# COMPUTE_CLUSTER0_CTL_CFG_PI register map
Vendor: Texas Instruments
Registers are 32-bit, read-write, reset 0x0 unless marked. A register's access mark holds for its fields unless they carry their own. Offsets are as the file gives them; [hi:lo] are bit positions; {n}, {i} and the like mark numbered series.

## COMPUTE_CLUSTER0_CTL_CFG_PI (part 2 of 2)
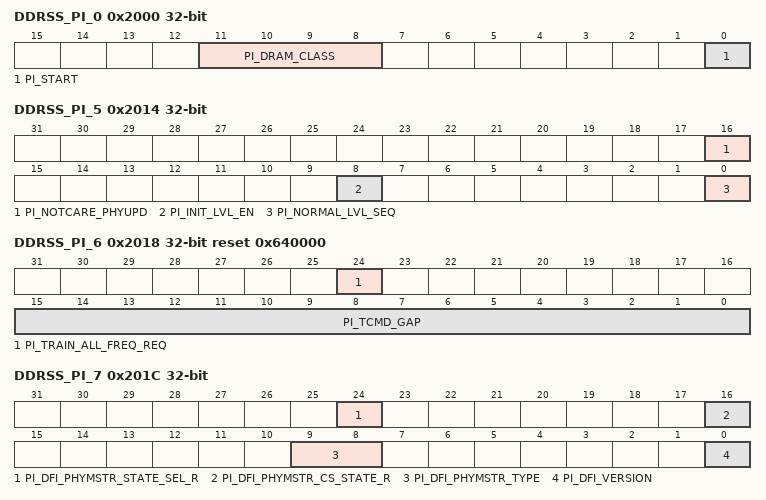
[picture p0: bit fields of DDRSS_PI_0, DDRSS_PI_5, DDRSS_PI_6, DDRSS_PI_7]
0x2000 DDRSS_PI_0
  [11:8] PI_DRAM_CLASS — Defines the memory class for the PI.Bh - LPDDR4All other values reserved
  [0] PI_START — Initiate command processing in the PI.
0x2004 DDRSS_PI_1 ro reset 0xCB1E3F21
  [31:0] PI_VERSION_0 — Holds the PI version number.
0x2008 DDRSS_PI_2 ro reset 0x78D9209
  [31:0] PI_VERSION_1 — Holds the PI version number.
0x200C DDRSS_PI_3 ro reset 0x1387
  [15:0] PI_ID — Holds the PI ID number.
0x2010 DDRSS_PI_4 ro
  [31:0] PI_UNUSED_REG_0 — Unused register
0x2014 DDRSS_PI_5
  [16] PI_NOTCARE_PHYUPD — Allow the PI to issue a master request to the controller if a phyupd_req from the PHY has been detected.
  [8] PI_INIT_LVL_EN — Enables the initial leveling sequence after PI initialization procedure.
  [0] PI_NORMAL_LVL_SEQ — Enable the PI to finish all the pending leveling before releasing the DFI bus.
0x2018 DDRSS_PI_6 access per field reset 0x640000
  [24] PI_TRAIN_ALL_FREQ_REQ wo — Triggers training for all supported frequencies in PI_FREQ_MAP.
  [15:0] PI_TCMD_GAP rw — Specifies the minimum gap in DFI clocks between two commands.
0x201C DDRSS_PI_7
  [24] PI_DFI_PHYMSTR_STATE_SEL_R — DFI PHY Master State Select: Indication from the PHY to the MC whether the requested memory state is IDLE or Self refresh.
  [16] PI_DFI_PHYMSTR_CS_STATE_R — This signal indicates the state of the DRAM when the PHY becomes the master.
  [9:8] PI_DFI_PHYMSTR_TYPE — DFI Master Request Type used for dfi 4.1 verision: This signal indicates the required state of DRAM when PHY becomes the master.
  [0] PI_DFI_VERSION — Define the DFI master version, set 1 for DFI4.1, set 0 for DFI4.0
0x2020 DDRSS_PI_8 ro
  [31:0] PI_TDFI_PHYMSTR_MAX — Indicates the maximum number of DFI clock cycles registered while the dfi_phymstr_req signal is asserted and the dfi_phymstr_ack signal is asserted.
0x2024 DDRSS_PI_9 ro
  [19:0] PI_TDFI_PHYMSTR_RESP — Indicates the maximum number of DFI clock cycles registered between a dfi_phymstr_req signal assertion and a dfi_phymstr_ack signal assertion.
0x2028 DDRSS_PI_10 ro
  [19:0] PI_TDFI_PHYUPD_RESP — Indicates the maximum number of DFI clock cycles registered between a dfi_phyupd_req signal assertion and a dfi_phyupd_ack signal assertion.
0x202C DDRSS_PI_11 ro
  [31:0] PI_TDFI_PHYUPD_MAX — Indicates the maximum number of DFI clock cycles registered while the dfi_phyupd_req signal is asserted and the dfi_phy_ack signal is asserted.
0x2030 DDRSS_PI_12
  [31:0] PI_FREQ_MAP — Frequency map for supported working frequencies.
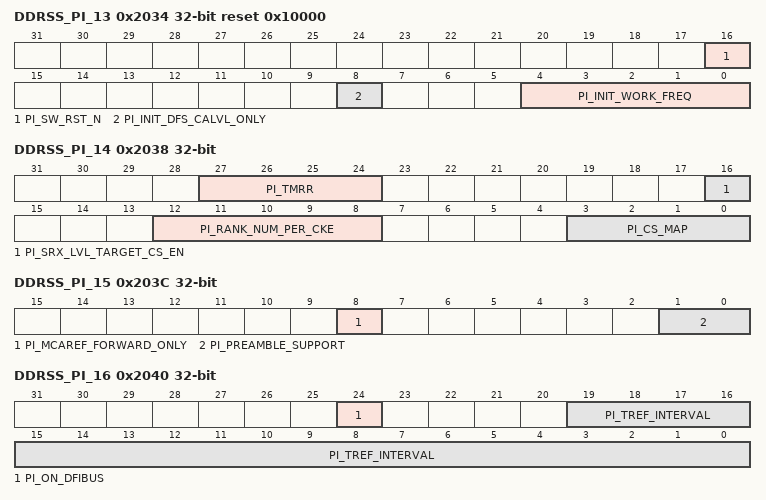
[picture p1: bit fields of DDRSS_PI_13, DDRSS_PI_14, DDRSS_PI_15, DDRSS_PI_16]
0x2034 DDRSS_PI_13 reset 0x10000
  [16] PI_SW_RST_N — User request to reset the whole PI except the parameter modules.
  [8] PI_INIT_DFS_CALVL_ONLY — Enables frequency training for CA leveling only.
  [4:0] PI_INIT_WORK_FREQ — Indicates the initial work frequency after initialization and initial leveling sequence.
0x2038 DDRSS_PI_14
  [27:24] PI_TMRR — DRAM tMRR value in memory clock cycles.
  [16] PI_SRX_LVL_TARGET_CS_EN — Defines self refresh exit trigger target rank/ranks training or all ranks training.
  [12:8] PI_RANK_NUM_PER_CKE — Defines the number of chip selects share one cke
  [3:0] PI_CS_MAP — Defines which chip selects are active.
0x203C DDRSS_PI_15
  [8] PI_MCAREF_FORWARD_ONLY — Controls the generation of AREF from the PI module or forward the MC received value.
  [1:0] PI_PREAMBLE_SUPPORT — Defines the read and write preamble length.
0x2040 DDRSS_PI_16 access per field
  [24] PI_ON_DFIBUS ro — Monitors the state of the PI controlling the DFI bus.
  [19:0] PI_TREF_INTERVAL rw — Defines the cycles between refreshes to different chip selects.
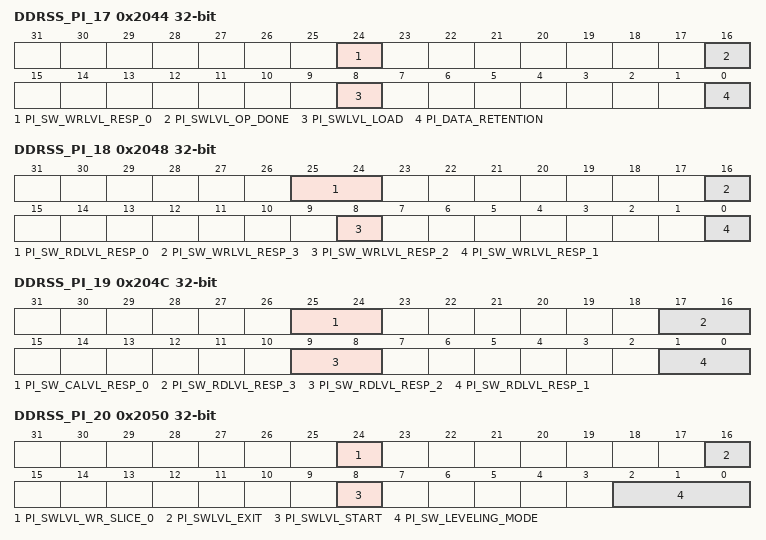
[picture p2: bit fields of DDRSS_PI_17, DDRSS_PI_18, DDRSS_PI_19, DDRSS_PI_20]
0x2044 DDRSS_PI_17 access per field
  [24] PI_SW_WRLVL_RESP_0 ro — Write leveling response for data slice 0.
  [16] PI_SWLVL_OP_DONE ro — Reports the status of the software leveling operation.
  [8] PI_SWLVL_LOAD wo — User request to load delays and execute software leveling.
  [0] PI_DATA_RETENTION ro — Monitors the readiness for the PHY to be put into data retention mode after pi_sref_entry req parameter has been written.
0x2048 DDRSS_PI_18 ro
  [25:24] PI_SW_RDLVL_RESP_0 — Read leveling response for data slice 0.
  [16] PI_SW_WRLVL_RESP_3 — Write leveling response for data slice 3.
  [8] PI_SW_WRLVL_RESP_2 — Write leveling response for data slice 2.
  [0] PI_SW_WRLVL_RESP_1 — Write leveling response for data slice 1.
0x204C DDRSS_PI_19 ro
  [25:24] PI_SW_CALVL_RESP_0 — CA leveling response for address slice 0.
  [17:16] PI_SW_RDLVL_RESP_3 — Read leveling response for data slice 3.
  [9:8] PI_SW_RDLVL_RESP_2 — Read leveling response for data slice 2.
  [1:0] PI_SW_RDLVL_RESP_1 — Read leveling response for data slice 1.
0x2050 DDRSS_PI_20 access per field
  [24] PI_SWLVL_WR_SLICE_0 wo — SW leveling write command in WDQ training.
  [16] PI_SWLVL_EXIT wo — User request to exit software leveling.
  [8] PI_SWLVL_START wo — User request to initiate software leveling of type in the SW_LEVELING_MODE parameter.
  [2:0] PI_SW_LEVELING_MODE rw — Defines the leveling operation for software leveling.
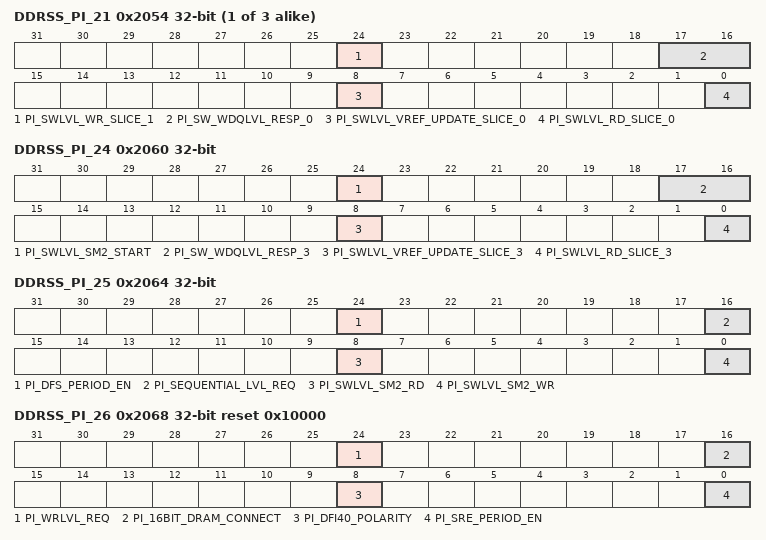
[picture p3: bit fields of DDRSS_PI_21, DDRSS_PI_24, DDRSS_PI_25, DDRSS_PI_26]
{0x2000+4i} DDRSS_PI_{i} access per field (i=21..23)
  [24] PI_SWLVL_WR_SLICE_{i-20} wo — SW leveling write command in WDQ training.
  [17:16] PI_SW_WDQLVL_RESP_{i-21} ro — Leveling response for data slice {i-21}.
  [8] PI_SWLVL_VREF_UPDATE_SLICE_{i-21} wo — SW leveling vref update command in WDQ training.
  [0] PI_SWLVL_RD_SLICE_{i-21} wo — SW leveling read command in WDQ training.
0x2060 DDRSS_PI_24 access per field
  [24] PI_SWLVL_SM2_START wo — SW leveling start command for stage 2.
  [17:16] PI_SW_WDQLVL_RESP_3 ro — Leveling response for data slice 3.
  [8] PI_SWLVL_VREF_UPDATE_SLICE_3 wo — SW leveling vref update command in WDQ training.
  [0] PI_SWLVL_RD_SLICE_3 wo — SW leveling read command in WDQ training.
0x2064 DDRSS_PI_25 access per field
  [24] PI_DFS_PERIOD_EN rw — Enable the DFS triggered periodic leveling.
  [16] PI_SEQUENTIAL_LVL_REQ wo — User request to initiate all possible leveling sequences.
  [8] PI_SWLVL_SM2_RD wo — SW leveling read command for stage 2.
  [0] PI_SWLVL_SM2_WR wo — SW leveling write command for stage 2.
0x2068 DDRSS_PI_26 access per field reset 0x10000
  [24] PI_WRLVL_REQ wo — User request to initiate write leveling.
  [16] PI_16BIT_DRAM_CONNECT rw — Enable 16/32 bit DRAM configuration.
  [8] PI_DFI40_POLARITY rw — Defines the polarity of the dfi_wrdata_cs_n/dfi_rddata_cs_n signals.
  [0] PI_SRE_PERIOD_EN rw — Enable the self refresh exit triggered periodic leveling.
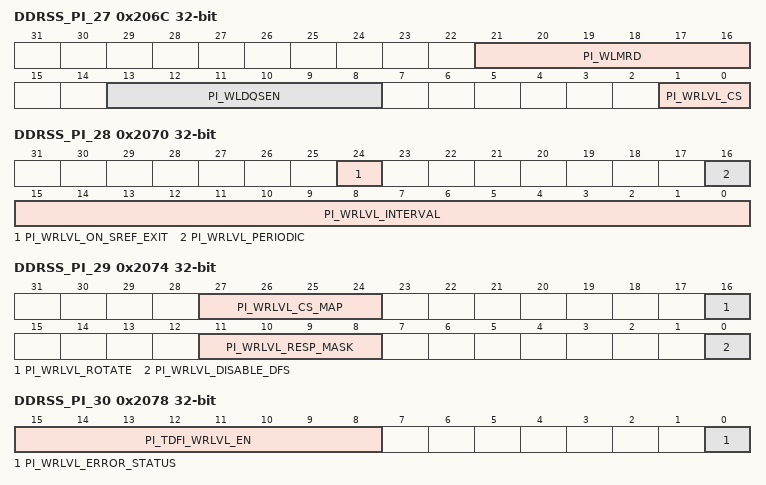
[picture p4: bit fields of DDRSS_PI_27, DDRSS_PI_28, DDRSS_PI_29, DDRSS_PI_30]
0x206C DDRSS_PI_27
  [21:16] PI_WLMRD — Delay from issuing MRS to first write leveling strobe.
  [13:8] PI_WLDQSEN — Delay from issuing MRS to first DQS strobe for write leveling.
  [1:0] PI_WRLVL_CS — Specifies the target chip select for the write leveling operation initiated through the WRLVL_REQ parameter.
0x2070 DDRSS_PI_28
  [24] PI_WRLVL_ON_SREF_EXIT — Enables automatic write leveling on a self-refresh exit.
  [16] PI_WRLVL_PERIODIC — Enables the use of the dfi_lvl_periodic signal during write leveling.
  [15:0] PI_WRLVL_INTERVAL — Number of long count sequences counted between automatic write leveling commands.
0x2074 DDRSS_PI_29
  [27:24] PI_WRLVL_CS_MAP — Defines the chip select map for write leveling operations.
  [16] PI_WRLVL_ROTATE — Enables rotational CS for counter triggered automatic write leveling.
  [11:8] PI_WRLVL_RESP_MASK — Mask for the dfi_wrlvl_resp signal during write leveling.
  [0] PI_WRLVL_DISABLE_DFS — Disable automatic write leveling on freq change.
0x2078 DDRSS_PI_30 access per field
  [15:8] PI_TDFI_WRLVL_EN rw — Defines the DFI tWRLVL_EN timing parameter (in DFI clocks), the minimum cycles from a dfi_wrlvl_en assertion to the first dfi_wrlvl_strobe assertion.
  [0] PI_WRLVL_ERROR_STATUS ro — Holds the error associated with the write level error interrupt.
0x207C DDRSS_PI_31
  [31:0] PI_TDFI_WRLVL_RESP — Defines the DFI tWRLVL_RESP timing parameter (in DFI clocks), the maximum cycles between a dfi_wrlvl_req assertion and a dfi_wrlvl_en assertion.
0x2080 DDRSS_PI_32
  [31:0] PI_TDFI_WRLVL_MAX — Defines the DFI tWRLVL_MAX timing parameter (in DFI clocks), the maximum cycles between a dfi_wrlvl_en assertion and a valid dfi_wrlvl_resp.
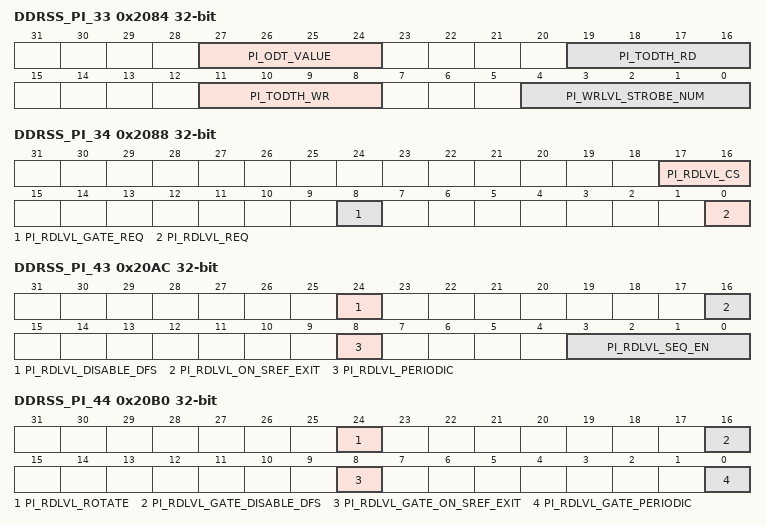
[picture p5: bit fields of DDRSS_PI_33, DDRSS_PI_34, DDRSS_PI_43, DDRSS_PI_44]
0x2084 DDRSS_PI_33
  [27:24] PI_ODT_VALUE — When using LPDDR4, this value will be driven out on the dfi_odt signal.
  [19:16] PI_TODTH_RD — Defines the minimum DRAM cycles of ODT high time for a read command, in memory clocks.
  [11:8] PI_TODTH_WR — Defines the minimum DRAM cycles of ODT high time for a write command, in memory clocks.
  [4:0] PI_WRLVL_STROBE_NUM — Defines the number of write leveling strobes generated.
0x2088 DDRSS_PI_34 access per field
  [17:16] PI_RDLVL_CS rw — Specifies the target chip select for the data eye training operation initiated through the RDLVL_REQ parameter or the gate training operation initiated through the RDLVL_GATE_REQ parameter.
  [8] PI_RDLVL_GATE_REQ wo — User request to initiate gate training.
  [0] PI_RDLVL_REQ wo — User request to initiate data eye training.
{0x2000+4i} DDRSS_PI_{i} (i=35..42)
  [31:0] PI_RDLVL_PAT_{i-35} — Non-default pattern {i-35} used for read data eye training of DDR4 or LPDDR4, and read dbi training of DDR4.
0x20AC DDRSS_PI_43
  [24] PI_RDLVL_DISABLE_DFS — Disables automatic data eye training on freq change.
  [16] PI_RDLVL_ON_SREF_EXIT — Enables automatic data eye training on a self-refresh exit.
  [8] PI_RDLVL_PERIODIC — Enables the use of the dfi_lvl_periodic signal during data eye training.
  [3:0] PI_RDLVL_SEQ_EN — Specifies the pattern, format and MPR for data eye training.
0x20B0 DDRSS_PI_44
  [24] PI_RDLVL_ROTATE — Enables rotational CS for interval data eye training.
  [16] PI_RDLVL_GATE_DISABLE_DFS — Disables automatic gate training on freq change.
  [8] PI_RDLVL_GATE_ON_SREF_EXIT — Enables automatic gate training on a self-refresh exit.
  [0] PI_RDLVL_GATE_PERIODIC — Enables the use of the dfi_lvl_periodic signal during gate training.
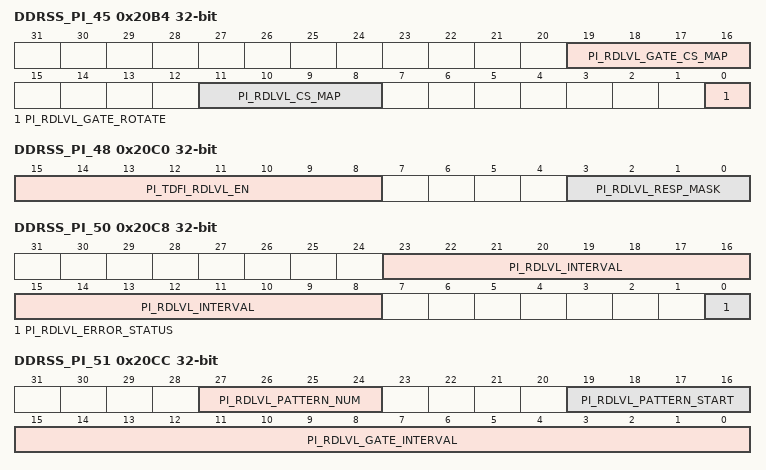
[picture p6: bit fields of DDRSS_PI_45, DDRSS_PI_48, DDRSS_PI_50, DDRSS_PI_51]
0x20B4 DDRSS_PI_45
  [19:16] PI_RDLVL_GATE_CS_MAP — Defines the chip select map for gate training operations.
  [11:8] PI_RDLVL_CS_MAP — Defines the chip select map for data eye training operations.
  [0] PI_RDLVL_GATE_ROTATE — Enables rotational CS for interval gate training.
0x20B8 DDRSS_PI_46
  [9:0] PI_TDFI_RDLVL_RR — Defines the DFI tRDLVL_RR timing parameter (in DFI clocks), the minimum cycles between read commands.
0x20BC DDRSS_PI_47
  [31:0] PI_TDFI_RDLVL_RESP — Defines the DFI tRDLVL_RESP timing parameter (in DFI clocks), the maximum cycles between a dfi_rdlvl_req or dfi_rdlvl_gate_req assertion and a dfi_rdlvl_en or dfi_rdlvl_gate_en assertion.
0x20C0 DDRSS_PI_48
  [15:8] PI_TDFI_RDLVL_EN — Defines the DFI tRDLVL_EN timing parameter (in DFI clocks), the minimum cycles from a dfi_rdlvl_en or dfi_rdlvl_gate_en assertion to the first read or MRR.
  [3:0] PI_RDLVL_RESP_MASK — Mask for the dfi_rdlvl_resp signal during data eye training.
0x20C4 DDRSS_PI_49
  [31:0] PI_TDFI_RDLVL_MAX — Defines the DFI tRDLVL_MAX timing parameter (in DFI clocks), the maximum cycles between a dfi_rdlvl_en or dfi_rdlvl_gate_en assertion and a valid dfi_rdlvl_resp.
0x20C8 DDRSS_PI_50 access per field
  [23:8] PI_RDLVL_INTERVAL rw — Number of long count sequences counted between automatic data eye training commands.
  [0] PI_RDLVL_ERROR_STATUS ro — Holds the error associated with the data eye training error or gate training error interrupt.
0x20CC DDRSS_PI_51
  [27:24] PI_RDLVL_PATTERN_NUM — Defines the number of pattern supported in read leveling.
  [19:16] PI_RDLVL_PATTERN_START — Defines the start pattern in read leveling.
  [15:0] PI_RDLVL_GATE_INTERVAL — Number of long count sequences counted between automatic gate training commands.
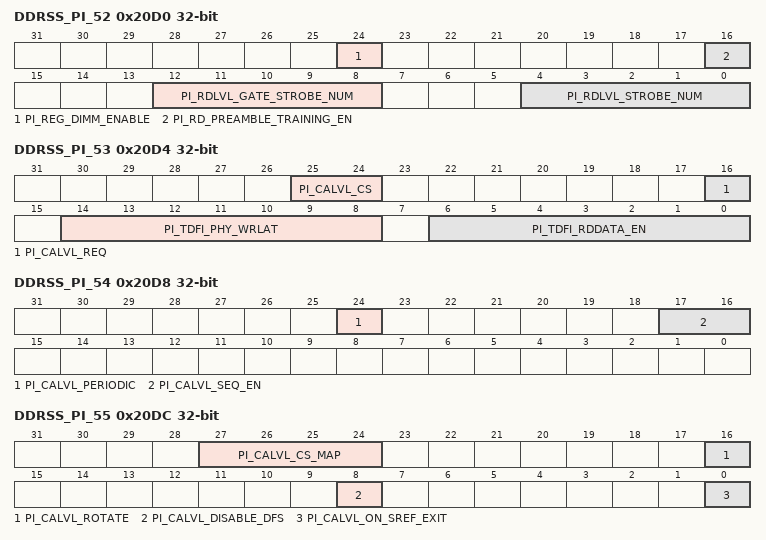
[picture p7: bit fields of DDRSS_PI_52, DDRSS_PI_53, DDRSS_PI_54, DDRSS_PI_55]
0x20D0 DDRSS_PI_52
  [24] PI_REG_DIMM_ENABLE — Enable registered DIMM operation.
  [16] PI_RD_PREAMBLE_TRAINING_EN — Enable read preamble training during gate training.
  [12:8] PI_RDLVL_GATE_STROBE_NUM — Defines the number of back to back MPC command in one read process in read gate training.
  [4:0] PI_RDLVL_STROBE_NUM — Defines the number of back to back MPC command in one read process in read eye training.
0x20D4 DDRSS_PI_53 access per field
  [25:24] PI_CALVL_CS rw — Specifies the target chip select for the CA training operation initiated through the CALVL_REQ parameter.
  [16] PI_CALVL_REQ wo — User request to initiate CA training.
  [14:8] PI_TDFI_PHY_WRLAT ro — Holds the calculated DFI tPHY_WRLAT timing parameter (in DFI PHY clocks), the maximum cycles between a write command and a dfi_wrdata_en assertion.
  [6:0] PI_TDFI_RDDATA_EN ro — Holds the calculated DFI tRDDATA_EN timing parameter (in DFI PHY clocks), the maximum cycles between a read command and a dfi_rddata_en assertion.
0x20D8 DDRSS_PI_54
  [24] PI_CALVL_PERIODIC — Enables the use of the dfi_lvl_periodic signal during CA training.
  [17:16] PI_CALVL_SEQ_EN — Specifies which CA training patterns will be used.
0x20DC DDRSS_PI_55
  [27:24] PI_CALVL_CS_MAP — Defines the chip select map for CA training operations.
  [16] PI_CALVL_ROTATE — Enables rotational CS for interval CA training.
  [8] PI_CALVL_DISABLE_DFS — Disables automatic CA training on freq change.
  [0] PI_CALVL_ON_SREF_EXIT — Enables automatic CA training on a self-refresh exit.
0x20E0 DDRSS_PI_56
  [7:0] PI_TDFI_CALVL_EN — Defines the DFI tCALVL_EN timing parameter (in DFI clocks), the minimum cycles between a dfi_calvl_en assertion and a dfi_cke de-assertion.
0x20E4 DDRSS_PI_57
  [31:0] PI_TDFI_CALVL_RESP — Defines the DFI tCALVL_RESP timing parameter (in DFI clocks), the maximum cycles between a dfi_calvl_req assertion and a dfi_calvl_en assertion.
0x20E8 DDRSS_PI_58
  [31:0] PI_TDFI_CALVL_MAX — Defines the DFI tCALVL_MAX timing parameter (in DFI clocks), the maximum cycles between a dfi_calvl_en assertion and a valid dfi_calvl_resp.
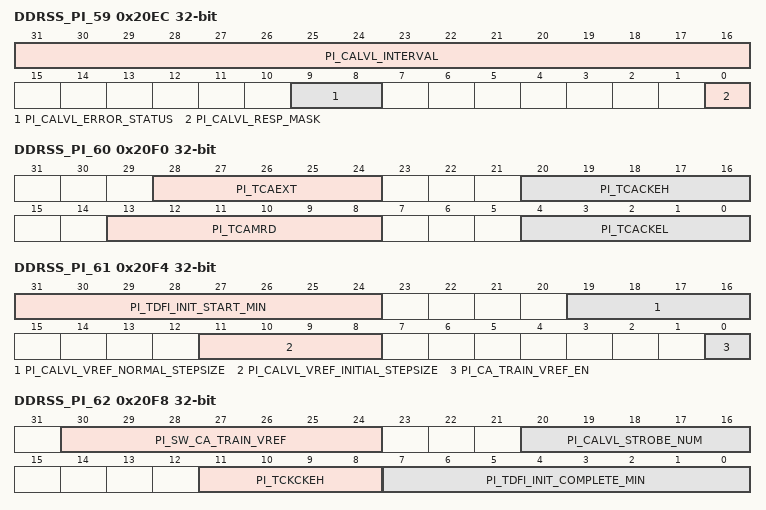
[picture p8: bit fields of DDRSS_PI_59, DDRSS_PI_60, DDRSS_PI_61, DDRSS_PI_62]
0x20EC DDRSS_PI_59 access per field
  [31:16] PI_CALVL_INTERVAL rw — Number of long count sequences counted between automatic CA training commands.
  [9:8] PI_CALVL_ERROR_STATUS ro — Holds the error associated with the CA training error interrupt.
  [0] PI_CALVL_RESP_MASK rw — Mask for the dfi_calvl_resp signal during CA training.
0x20F0 DDRSS_PI_60
  [28:24] PI_TCAEXT — DRAM tCAEXT value in memory cycles.
  [20:16] PI_TCACKEH — DRAM tCACKEH value in memory cycles.
  [13:8] PI_TCAMRD — DRAM tCAMRD value in memory cycles.
  [4:0] PI_TCACKEL — DRAM tCACKEL value in memory cycles.
0x20F4 DDRSS_PI_61
  [31:24] PI_TDFI_INIT_START_MIN — Minimum number of DFI clocks before dfi_init_start can be driven after a previous command/training event.
  [19:16] PI_CALVL_VREF_NORMAL_STEPSIZE — The adjust step for the post-initial Vref(ca) training.
  [11:8] PI_CALVL_VREF_INITIAL_STEPSIZE — The adjust step for the initial Vref(ca) training.
  [0] PI_CA_TRAIN_VREF_EN — Control for VREF training during CA training post power-on initialization.
0x20F8 DDRSS_PI_62
  [30:24] PI_SW_CA_TRAIN_VREF — The Vref value which is set for SW step by step CA training.
  [20:16] PI_CALVL_STROBE_NUM — The consecutive dfi_calvl_strobe number when updating the CA vref data.
  [11:8] PI_TCKCKEH — DRAM tCKELCK Clock and command valid before CKE HIGH.
  [7:0] PI_TDFI_INIT_COMPLETE_MIN — Minimum number of DFI clocks from dfi_init_complete to a command/training event.
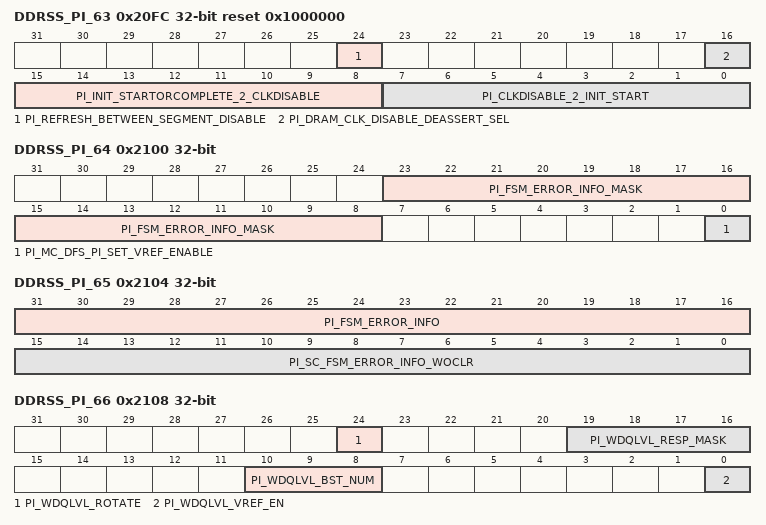
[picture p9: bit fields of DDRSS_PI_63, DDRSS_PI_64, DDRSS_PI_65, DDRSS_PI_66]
0x20FC DDRSS_PI_63 reset 0x1000000
  [24] PI_REFRESH_BETWEEN_SEGMENT_DISABLE — Disable the refresh between CA first and second segment training.
  [16] PI_DRAM_CLK_DISABLE_DEASSERT_SEL — Indicate dfi_dram_clk_disable deassert following dfi_init_start deassert or dfi_init_complete assert.
  [15:8] PI_INIT_STARTORCOMPLETE_2_CLKDISABLE — Defines the delay from deasserting of dfi_init_start or asserting of dfi_init_complete to deasserting of dfi_dram_clk_disable in DFI clock.
  [7:0] PI_CLKDISABLE_2_INIT_START — Defines the delay from the asserting of dfi_dram_clk_disable to the asserting of dfi_init_start in DFI clock.
0x2100 DDRSS_PI_64
  [23:8] PI_FSM_ERROR_INFO_MASK
  [0] PI_MC_DFS_PI_SET_VREF_ENABLE — Enable the PI to set VREF value after DFS issued by MC.
0x2104 DDRSS_PI_65 access per field
  [31:16] PI_FSM_ERROR_INFO ro — Gather each fsm error bit.
  [15:0] PI_SC_FSM_ERROR_INFO_WOCLR wo — PI FSM Error Info.
0x2108 DDRSS_PI_66
  [24] PI_WDQLVL_ROTATE — Enables write DQ training rotate for interval training.
  [19:16] PI_WDQLVL_RESP_MASK — Write DQ training response mask.
  [10:8] PI_WDQLVL_BST_NUM — Defines the number of write/read bursts issued at each step in write DQ training.
  [0] PI_WDQLVL_VREF_EN — Control for VREF training as part of non-initialization write DQ training.
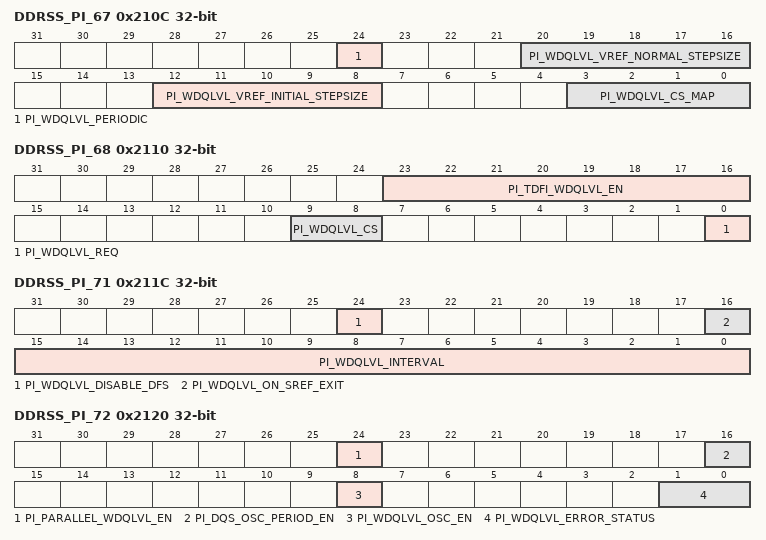
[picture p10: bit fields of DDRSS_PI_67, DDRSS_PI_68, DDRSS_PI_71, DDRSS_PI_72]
0x210C DDRSS_PI_67
  [24] PI_WDQLVL_PERIODIC — Enables periodic write DQ training.
  [20:16] PI_WDQLVL_VREF_NORMAL_STEPSIZE — Write DQ training vref step size for post_initial training.
  [12:8] PI_WDQLVL_VREF_INITIAL_STEPSIZE — Write DQ training vref step size for initial training.
  [3:0] PI_WDQLVL_CS_MAP — Map of CS's included in write DQ training sequence.
0x2110 DDRSS_PI_68 access per field
  [23:16] PI_TDFI_WDQLVL_EN rw — DFI timing param tWDQLVL_EN.
  [9:8] PI_WDQLVL_CS rw — Write DQ training target chip select.
  [0] PI_WDQLVL_REQ wo — SW write to initiate Write DQ training request.
0x2114 DDRSS_PI_69
  [31:0] PI_TDFI_WDQLVL_RESP — DFI timing param tWDQLVL_RESP.
0x2118 DDRSS_PI_70
  [31:0] PI_TDFI_WDQLVL_MAX — DFI timing param tWDQLVL_MAX.
0x211C DDRSS_PI_71
  [24] PI_WDQLVL_DISABLE_DFS — Disable automatic write DQ training on freq change.
  [16] PI_WDQLVL_ON_SREF_EXIT — Issue a write DQ training command on self-refresh exit.
  [15:0] PI_WDQLVL_INTERVAL — Sets the maximum number of long count sequences allowed between automatic write DQ training operations.
0x2120 DDRSS_PI_72 access per field
  [24] PI_PARALLEL_WDQLVL_EN rw — Enable per rank parallel Write DQ training for LPDDR4,
  [16] PI_DQS_OSC_PERIOD_EN rw — Enable for DQS oscillator triggered periodic write DQ training,
  [8] PI_WDQLVL_OSC_EN rw — Enable for DQS oscillator triggered write DQ training,
  [1:0] PI_WDQLVL_ERROR_STATUS ro — Holds the error associated with the write dq level error interrupt.
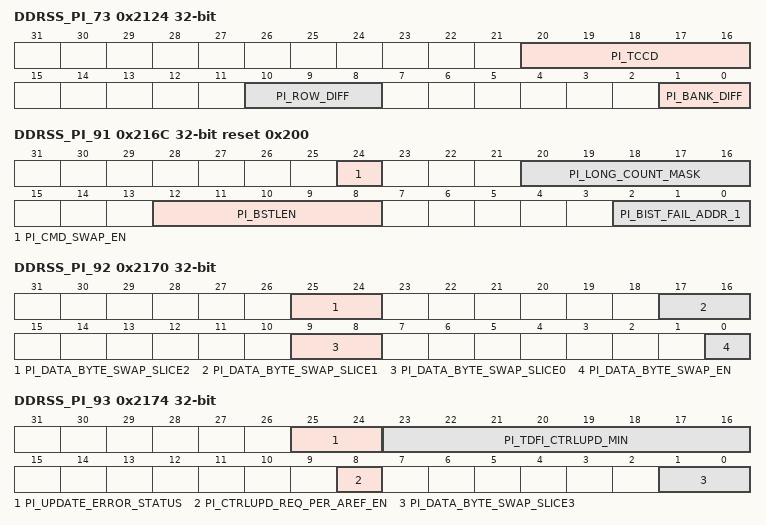
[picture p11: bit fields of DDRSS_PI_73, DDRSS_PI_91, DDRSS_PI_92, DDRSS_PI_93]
0x2124 DDRSS_PI_73
  [20:16] PI_TCCD — DRAM CAS-to-CAS value in cycles.
  [10:8] PI_ROW_DIFF — Difference between number of address pins available and number being used.
  [1:0] PI_BANK_DIFF — Difference between number of bank pins available and number being used.
0x2128 DDRSS_PI_74 reset 0x2000200 (reset mask 0xF0F0F0F)
0x212C DDRSS_PI_75 reset 0x1000100 (reset mask 0xF0F0F0F)
0x2130 DDRSS_PI_76 reset 0x1000000 (reset mask 0xF0F0F0F)
0x2134 DDRSS_PI_77 reset 0x2000200 (reset mask 0xF0F0F0F)
0x2138 DDRSS_PI_78 reset 0x200 (reset mask 0xF0F0F)
0x213C DDRSS_PI_79 ro
  [27:0] PI_INT_STATUS — Status of interrupt features in the PI.
0x2140 DDRSS_PI_80 wo
  [26:0] PI_INT_ACK — Clear the corresponding interrupt bit of the PI_INT_STATUS parameter.
0x2144 DDRSS_PI_81
  [27:0] PI_INT_MASK — Mask for PI_int signals from the PI_INT_STATUS parameter.
{0x2000+4i} DDRSS_PI_{i} ro (i=82..85)
  [31:0] PI_BIST_EXP_DATA_{i-82} — Expected data on BIST error.
{0x2000+4i} DDRSS_PI_{i} ro (i=86..89)
  [31:0] PI_BIST_FAIL_DATA_{i-86} — Actual data on BIST error.
0x2168 DDRSS_PI_90 ro
  [31:0] PI_BIST_FAIL_ADDR_0 — The burst aligned address of BIST error.
0x216C DDRSS_PI_91 access per field reset 0x200
  [24] PI_CMD_SWAP_EN rw — Command pin swap function enable
  [20:16] PI_LONG_COUNT_MASK rw — Reduces the length of the long counter from 1024 cycles.
  [12:8] PI_BSTLEN rw — Encoded burst length sent to DRAMs during initialization.
  [2:0] PI_BIST_FAIL_ADDR_1 ro — The burst aligned address of BIST error.
0x2170 DDRSS_PI_92
  [25:24] PI_DATA_BYTE_SWAP_SLICE2 — DATA pin 2 mux selector
  [17:16] PI_DATA_BYTE_SWAP_SLICE1 — DATA pin 1 mux selector
  [9:8] PI_DATA_BYTE_SWAP_SLICE0 — DATA pin 0 mux selector
  [0] PI_DATA_BYTE_SWAP_EN — DATA pin swap function enable
0x2174 DDRSS_PI_93 access per field
  [25:24] PI_UPDATE_ERROR_STATUS ro — Identifies the source of any DFI PI-initiated update errors.
  [23:16] PI_TDFI_CTRLUPD_MIN rw — Reports the DFI tCTRLUPD_MIN timing parameter (in DFI clocks), the minimum cycles that dfi_ctrlupd_req must be asserted.
  [8] PI_CTRLUPD_REQ_PER_AREF_EN rw — Enable an automatic PI initiated update (dfi_ctrlupd_req) after every refresh.
  [1:0] PI_DATA_BYTE_SWAP_SLICE3 rw — DATA pin 3 mux selector
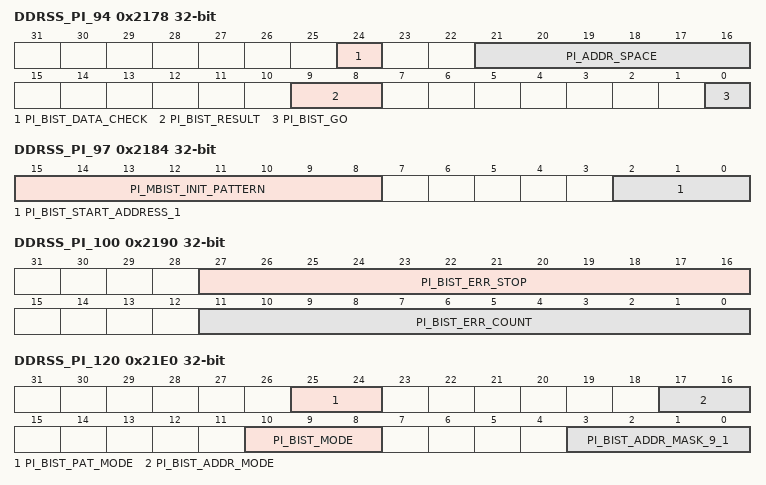
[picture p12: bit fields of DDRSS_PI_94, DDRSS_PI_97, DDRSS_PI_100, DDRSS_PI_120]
0x2178 DDRSS_PI_94 access per field
  [24] PI_BIST_DATA_CHECK rw — Enable data checking with BIST operation.
  [21:16] PI_ADDR_SPACE rw — Sets the number of address bits to check during BIST operation.
  [9:8] PI_BIST_RESULT ro — BIST operation status (pass/fail).
  [0] PI_BIST_GO rw — Initiate a BIST operation.
0x217C DDRSS_PI_95
  [0] PI_BIST_ADDR_CHECK — Enable address checking with BIST operation.
0x2180 DDRSS_PI_96
  [31:0] PI_BIST_START_ADDRESS_0 — Start BIST checking at this address.
0x2184 DDRSS_PI_97
  [15:8] PI_MBIST_INIT_PATTERN — PI mbist data check, random lfsr pattern mode init pattern seed.
  [2:0] PI_BIST_START_ADDRESS_1 — Start BIST checking at this address.
0x2188 DDRSS_PI_98
  [31:0] PI_BIST_DATA_MASK_0 — Mask applied to data for BIST error checking.
0x218C DDRSS_PI_99
  [31:0] PI_BIST_DATA_MASK_1 — Mask applied to data for BIST error checking.
0x2190 DDRSS_PI_100 access per field
  [27:16] PI_BIST_ERR_STOP rw — Defines the maximum number of error occurrences allowed prior to quitting when the BIST_TEST_MODE parameter is set to 1, 2 or 3.
  [11:0] PI_BIST_ERR_COUNT ro — Indicates the number of BIST errors found when the BIST_TEST_MODE parameter is set to 1, 2 or 3.
0x2194 DDRSS_PI_101
  [31:0] PI_BIST_ADDR_MASK_0_0 — Defines an address to be masked during the BIST operation..
0x2198 DDRSS_PI_102
  [3:0] PI_BIST_ADDR_MASK_0_1 — Defines an address to be masked during the BIST operation..
0x219C DDRSS_PI_103
  [31:0] PI_BIST_ADDR_MASK_1_0 — Defines an address to be masked during the BIST operation..
0x21A0 DDRSS_PI_104
  [3:0] PI_BIST_ADDR_MASK_1_1 — Defines an address to be masked during the BIST operation..
0x21A4 DDRSS_PI_105
  [31:0] PI_BIST_ADDR_MASK_2_0 — Defines an address to be masked during the BIST operation..
0x21A8 DDRSS_PI_106
  [3:0] PI_BIST_ADDR_MASK_2_1 — Defines an address to be masked during the BIST operation..
0x21AC DDRSS_PI_107
  [31:0] PI_BIST_ADDR_MASK_3_0 — Defines an address to be masked during the BIST operation..
0x21B0 DDRSS_PI_108
  [3:0] PI_BIST_ADDR_MASK_3_1 — Defines an address to be masked during the BIST operation..
0x21B4 DDRSS_PI_109
  [31:0] PI_BIST_ADDR_MASK_4_0 — Defines an address to be masked during the BIST operation..
0x21B8 DDRSS_PI_110
  [3:0] PI_BIST_ADDR_MASK_4_1 — Defines an address to be masked during the BIST operation..
0x21BC DDRSS_PI_111
  [31:0] PI_BIST_ADDR_MASK_5_0 — Defines an address to be masked during the BIST operation..
0x21C0 DDRSS_PI_112
  [3:0] PI_BIST_ADDR_MASK_5_1 — Defines an address to be masked during the BIST operation..
0x21C4 DDRSS_PI_113
  [31:0] PI_BIST_ADDR_MASK_6_0 — Defines an address to be masked during the BIST operation..
0x21C8 DDRSS_PI_114
  [3:0] PI_BIST_ADDR_MASK_6_1 — Defines an address to be masked during the BIST operation..
0x21CC DDRSS_PI_115
  [31:0] PI_BIST_ADDR_MASK_7_0 — Defines an address to be masked during the BIST operation..
0x21D0 DDRSS_PI_116
  [3:0] PI_BIST_ADDR_MASK_7_1 — Defines an address to be masked during the BIST operation..
0x21D4 DDRSS_PI_117
  [31:0] PI_BIST_ADDR_MASK_8_0 — Defines an address to be masked during the BIST operation..
0x21D8 DDRSS_PI_118
  [3:0] PI_BIST_ADDR_MASK_8_1 — Defines an address to be masked during the BIST operation..
0x21DC DDRSS_PI_119
  [31:0] PI_BIST_ADDR_MASK_9_0 — Defines an address to be masked during the BIST operation..
0x21E0 DDRSS_PI_120
  [25:24] PI_BIST_PAT_MODE — Sets the pattern mode of BIST.
  [17:16] PI_BIST_ADDR_MODE — Sets the address traversing order of BIST.
  [10:8] PI_BIST_MODE — Sets the BIST data checking mode.
  [3:0] PI_BIST_ADDR_MASK_9_1 — Defines an address to be masked during the BIST operation..
{0x2000+4i} DDRSS_PI_{i} (i=121..124)
  [31:0] PI_BIST_USER_PAT_{i-121} — Sets the user-specified pattern of BIST.
0x21F4 DDRSS_PI_125
  [3:0] PI_BIST_PAT_NUM — Sets the max used pattern number of BIST from a total of 8 built-in patterns.
{0x2000+4i} DDRSS_PI_{i} (i=126..133)
  [29:0] PI_BIST_STAGE_{i-126} — Sets the programmable algorithm of each stage X when pi_bist_mmode = 'h4.
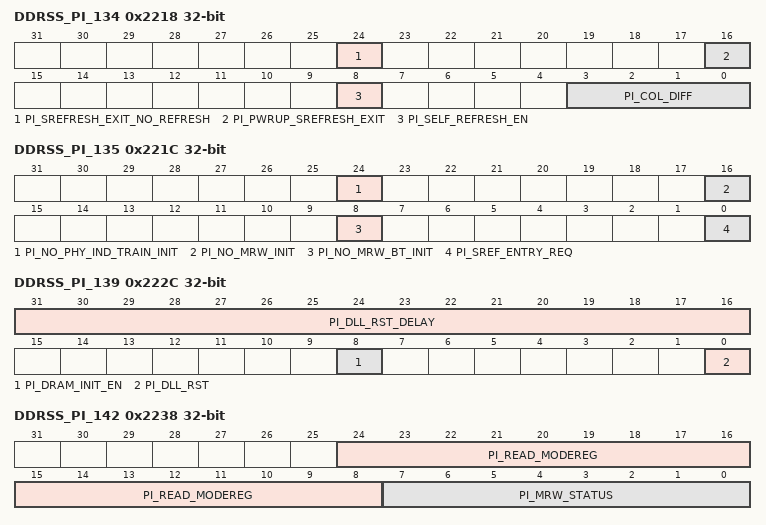
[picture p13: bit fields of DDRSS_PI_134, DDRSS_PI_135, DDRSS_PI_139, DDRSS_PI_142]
0x2218 DDRSS_PI_134
  [24] PI_SREFRESH_EXIT_NO_REFRESH — Disables the automatic refresh request associated with self-refresh exit.
  [16] PI_PWRUP_SREFRESH_EXIT — Allow powerup via self-refresh instead of full memory initialization.
  [8] PI_SELF_REFRESH_EN — Control for PI to enable self refresh mode.
  [3:0] PI_COL_DIFF — Difference between number of column pins available and number being used.
0x221C DDRSS_PI_135 access per field
  [24] PI_NO_PHY_IND_TRAIN_INIT rw — Disable PHY Independent Training during initialization.
  [16] PI_NO_MRW_INIT rw — Disable MRW commands after training during initialization.
  [8] PI_NO_MRW_BT_INIT rw — Disable MRW commands before training during initialization.
  [0] PI_SREF_ENTRY_REQ wo — In PI power up data retention, PI can issued sref entry command.
0x2220 DDRSS_PI_136
  [0] PI_NO_AUTO_MRR_INIT — Disable MRR commands during initialization.
0x2224 DDRSS_PI_137
  [31:0] PI_TRST_PWRON — Duration of memory reset during power-on initialization.
0x2228 DDRSS_PI_138
  [31:0] PI_CKE_INACTIVE — Number of cycles after reset before CKE will be active.
0x222C DDRSS_PI_139
  [31:16] PI_DLL_RST_DELAY — Minimum cycles required for DLL reset signal dll_rst_n to be held.
  [8] PI_DRAM_INIT_EN — Control for the initialization of DRAM by the PI.
  [0] PI_DLL_RST — Enables use of the DLL reset (dll_rst_n).
0x2230 DDRSS_PI_140
  [7:0] PI_DLL_RST_ADJ_DLY — Minimum cycles after setting master delay in DLL until the DLL reset signal dll_rst_n may be asserted.
0x2234 DDRSS_PI_141
  [25:0] PI_WRITE_MODEREG — Write memory mode register data to the DRAMs.
0x2238 DDRSS_PI_142 access per field
  [24:8] PI_READ_MODEREG rw — Read the specified memory mode register from specified chip when start bit set.
  [7:0] PI_MRW_STATUS ro — Write memory mode register status.
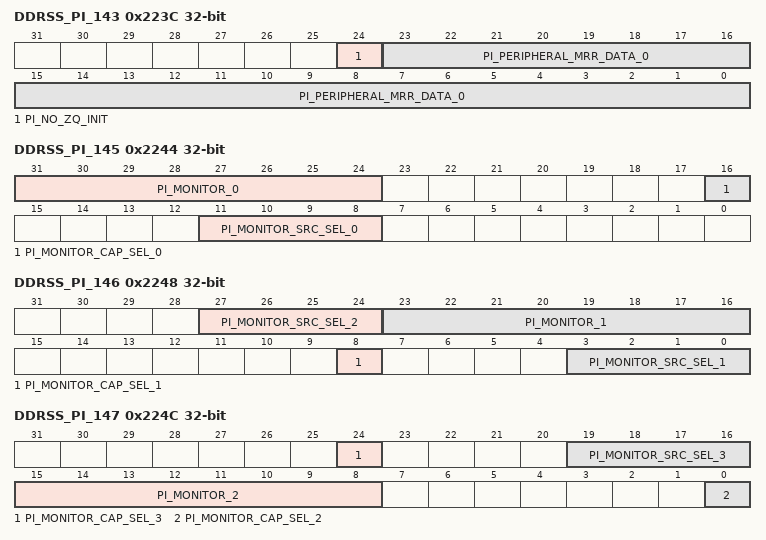
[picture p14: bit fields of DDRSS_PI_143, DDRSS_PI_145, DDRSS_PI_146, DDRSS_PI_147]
0x223C DDRSS_PI_143 access per field
  [24] PI_NO_ZQ_INIT rw — Disable ZQ operations during initialization.
  [23:0] PI_PERIPHERAL_MRR_DATA_0 ro — Data and chip returned from memory mode register read requested by the READ_MODEREG parameter, Bits (
0x2240 DDRSS_PI_144 access per field
  [16] PI_ZQ_REQ_PENDING ro — Indicates that a ZQ command is currently in progress or waiting to run.
0x2244 DDRSS_PI_145 access per field
  [31:24] PI_MONITOR_0 ro — Monitor register 0.
  [16] PI_MONITOR_CAP_SEL_0 rw — Selection of captures for pi_monitor_0.
  [11:8] PI_MONITOR_SRC_SEL_0 rw — Selection of sources for pi_monitor_0.
0x2248 DDRSS_PI_146 access per field
  [27:24] PI_MONITOR_SRC_SEL_2 rw — Selection of sources for pi_monitor_2.
  [23:16] PI_MONITOR_1 ro — Monitor register 1.
  [8] PI_MONITOR_CAP_SEL_1 rw — Selection of captures for pi_monitor_1.
  [3:0] PI_MONITOR_SRC_SEL_1 rw — Selection of sources for pi_monitor_1.
0x224C DDRSS_PI_147 access per field
  [24] PI_MONITOR_CAP_SEL_3 rw — Selection of captures for pi_monitor_3.
  [19:16] PI_MONITOR_SRC_SEL_3 rw — Selection of sources for pi_monitor_3.
  [15:8] PI_MONITOR_2 ro — Monitor register 2.
  [0] PI_MONITOR_CAP_SEL_2 rw — Selection of captures for pi_monitor_2.
0x2250 DDRSS_PI_148 access per field
  [31:24] PI_MONITOR_4 ro — Monitor register 4.
  [16] PI_MONITOR_CAP_SEL_4 rw — Selection of captures for pi_monitor_4.
  [11:8] PI_MONITOR_SRC_SEL_4 rw — Selection of sources for pi_monitor_4.
  [7:0] PI_MONITOR_3 ro — Monitor register 3.
0x2254 DDRSS_PI_149 access per field
  [27:24] PI_MONITOR_SRC_SEL_6 rw — Selection of sources for pi_monitor_6.
  [23:16] PI_MONITOR_5 ro — Monitor register 5.
  [8] PI_MONITOR_CAP_SEL_5 rw — Selection of captures for pi_monitor_5.
  [3:0] PI_MONITOR_SRC_SEL_5 rw — Selection of sources for pi_monitor_5.
0x2258 DDRSS_PI_150 access per field
  [24] PI_MONITOR_CAP_SEL_7 rw — Selection of captures for pi_monitor_7.
  [19:16] PI_MONITOR_SRC_SEL_7 rw — Selection of sources for pi_monitor_7.
  [15:8] PI_MONITOR_6 ro — Monitor register 6.
  [0] PI_MONITOR_CAP_SEL_6 rw — Selection of captures for pi_monitor_6.
0x225C DDRSS_PI_151 ro
  [7:0] PI_MONITOR_7 — Monitor register 7.
0x2260 DDRSS_PI_152 wo
  [7:0] PI_MONITOR_STROBE — Strobe the pi_monitor once.
0x2264 DDRSS_PI_153 access per field
  [20:16] PI_FREQ_RETENTION_NUM rw — Monitor active freq number in PI for data_retention
  [12:8] PI_FREQ_NUMBER_STATUS ro — Monitor active freq number in PI.
  [0] PI_DLL_LOCK ro — Monitor dfi_init_complete from PHY.
0x2268 DDRSS_PI_154
  [16] PI_POWER_REDUC_EN — PI Power reduction enable,
  [1:0] PI_PHYMSTR_TYPE — Defines how the controller should set the state of DRAM before turning control of the DFI bus over to the PI.
{0x2000+4i} DDRSS_PI_{i} (reset mask 0x1010101) (i=155..158)
0x227C DDRSS_PI_159
  [16:8] PI_TREFBW_THR — Threshold value to control the AREF command interval.
  [7:0] PI_WRLVL_MAX_STROBE_PEND — Defines the maximum number of wrlvl_strobes that be accumulated before an AREF is prevented from being generated.
0x2280 DDRSS_PI_160
  [4:0] PI_FREQ_CHANGE_REG_COPY — In non-DFI 4.0 mode, contains the frequency copy value.
0x2284 DDRSS_PI_161
  [27:24] PI_CATR — It indicates LP4 DRAM CA terminition ON/OFF state.
  [16] PI_PARALLEL_CALVL_EN — Enable parallel channel CA training for LPDDR4.
  [0] PI_FREQ_SEL_FROM_REGIF — In non-DFI 4.0 mode, user select the frequency copies from pi_freq_change_reg_copy.
0x2288 DDRSS_PI_162
  [24] PI_NOTCARE_MC_INIT_START — Defines whether PI waits for the controller to initiate dfi_init_start before PI memory initialization,
  [16] PI_DISCONNECT_MC — PI disconnects the controller from the PHY,
  [8] PI_MASK_INIT_COMPLETE — Enable the masking of the dfi_init_complete signal back to the controller,
  [0] PI_NO_CATR_READ — Defines how the LPDDR4 termination status is determined.
0x228C DDRSS_PI_163
  [31:24] PI_TSDO_F2 — The delay from the read preamble training MRS command to the data strobe drive out for frequency set 2, in PI clocks
  [23:16] PI_TSDO_F1 — The delay from the read preamble training MRS command to the data strobe drive out for frequency set 1, in PI clocks
  [15:8] PI_TSDO_F0 — The delay from the read preamble training MRS command to the data strobe drive out for frequency set 0, in PI clocks
  [0] PI_TRACE_MC_MR13 — Defines whether PI monitors controller mr13 mrw or not.
0x2290 DDRSS_PI_164
  [7:0] PI_TDELAY_RDWR_2_BUS_IDLE_F0 — The delay from read or write to bus idle for frequency set 0.
0x2294 DDRSS_PI_165
  [7:0] PI_TDELAY_RDWR_2_BUS_IDLE_F1 — The delay from read or write to bus idle for frequency set 1.
0x2298 DDRSS_PI_166
  [19:8] PI_ZQINIT_F0 — Number of cycles needed for a ZQINIT command for frequency set 0.
  [7:0] PI_TDELAY_RDWR_2_BUS_IDLE_F2 — The delay from read or write to bus idle for frequency set 2.
0x229C DDRSS_PI_167
  [27:16] PI_ZQINIT_F2 — Number of cycles needed for a ZQINIT command for frequency set 2.
  [11:0] PI_ZQINIT_F1 — Number of cycles needed for a ZQINIT command for frequency set 1.
0x22A0 DDRSS_PI_168
  [30:24] PI_CASLAT_LIN_F1 — Sets latency from read command sent to data received from/to controller for frequency set 1.
  [22:16] PI_WRLAT_F1 — DRAM WRLAT value in cycles for frequency set 1.
  [14:8] PI_CASLAT_LIN_F0 — Sets latency from read command sent to data received from/to controller for frequency set 0.
  [6:0] PI_WRLAT_F0 — DRAM WRLAT value in cycles for frequency set 0.
0x22A4 DDRSS_PI_169
  [25:16] PI_TRFC_F0 — DRAM tRFC value in memory clocks for frequency set 0.
  [14:8] PI_CASLAT_LIN_F2 — Sets latency from read command sent to data received from/to controller for frequency set 2.
  [6:0] PI_WRLAT_F2 — DRAM WRLAT value in cycles for frequency set 2.
0x22A8 DDRSS_PI_170
  [19:0] PI_TREF_F0 — DRAM tREF value in memory clocks for frequency set 0.
0x22AC DDRSS_PI_171
  [9:0] PI_TRFC_F1 — DRAM tRFC value in memory clocks for frequency set 1.
0x22B0 DDRSS_PI_172
  [19:0] PI_TREF_F1 — DRAM tREF value in memory clocks for frequency set 1.
0x22B4 DDRSS_PI_173
  [9:0] PI_TRFC_F2 — DRAM tRFC value in memory clocks for frequency set 2.
0x22B8 DDRSS_PI_174 reset 0x2000000
  [27:24] PI_TDFI_CTRL_DELAY_F0 — Defines the DFI tCTRL_DELAY timing parameter (in DFI clocks) for frequency set 0, the delay between a DFI command change and a memory command.
  [19:0] PI_TREF_F2 — DRAM tREF value in memory clocks for frequency set 2.
0x22BC DDRSS_PI_175 reset 0x202
  [25:24] PI_WRLVL_EN_F1 — Enable the PI write leveling module for frequency set 1.
  [17:16] PI_WRLVL_EN_F0 — Enable the PI write leveling module for frequency set 0.
  [11:8] PI_TDFI_CTRL_DELAY_F2 — Defines the DFI tCTRL_DELAY timing parameter (in DFI clocks) for frequency set 2, the delay between a DFI command change and a memory command.
  [3:0] PI_TDFI_CTRL_DELAY_F1 — Defines the DFI tCTRL_DELAY timing parameter (in DFI clocks) for frequency set 1, the delay between a DFI command change and a memory command.
0x22C0 DDRSS_PI_176
  [17:8] PI_TDFI_WRLVL_WW_F0 — Defines the DFI tWRLVL_WW timing parameter (in DFI clocks) for frequency set 0, the minimum cycles between dfi_wrlvl_strobe assertions.
  [1:0] PI_WRLVL_EN_F2 — Enable the PI write leveling module for frequency set 2.
0x22C4 DDRSS_PI_177
  [25:16] PI_TDFI_WRLVL_WW_F2 — Defines the DFI tWRLVL_WW timing parameter (in DFI clocks) for frequency set 2, the minimum cycles between dfi_wrlvl_strobe assertions.
  [9:0] PI_TDFI_WRLVL_WW_F1 — Defines the DFI tWRLVL_WW timing parameter (in DFI clocks) for frequency set 1, the minimum cycles between dfi_wrlvl_strobe assertions.
0x22C8 DDRSS_PI_178
  [24] PI_ODT_EN_F1 — Enable support of DRAM ODT.
  [23:16] PI_TODTL_2CMD_F1 — Defines the DRAM delay from an ODT de-assertion to the next non-write, non-read command for frequency set 1.
  [8] PI_ODT_EN_F0 — Enable support of DRAM ODT.
  [7:0] PI_TODTL_2CMD_F0 — Defines the DRAM delay from an ODT de-assertion to the next non-write, non-read command for frequency set 0.
0x22CC DDRSS_PI_179
  [27:24] PI_TODTON_MIN_F0 — Defines the point in time when the device termination circuit leaves High-Z and ODT resistance begins to turn on for frequency set 0.
  [19:16] PI_ODTLON_F0 — Defines the latency from a CAS-2 command to the tODTon reference for frequency set 0.
  [8] PI_ODT_EN_F2 — Enable support of DRAM ODT.
  [7:0] PI_TODTL_2CMD_F2 — Defines the DRAM delay from an ODT de-assertion to the next non-write, non-read command for frequency set 2.
0x22D0 DDRSS_PI_180
  [27:24] PI_TODTON_MIN_F2 — Defines the point in time when the device termination circuit leaves High-Z and ODT resistance begins to turn on for frequency set 2.
  [19:16] PI_ODTLON_F2 — Defines the latency from a CAS-2 command to the tODTon reference for frequency set 2.
  [11:8] PI_TODTON_MIN_F1 — Defines the point in time when the device termination circuit leaves High-Z and ODT resistance begins to turn on for frequency set 1.
  [3:0] PI_ODTLON_F1 — Defines the latency from a CAS-2 command to the tODTon reference for frequency set 1.
0x22D4 DDRSS_PI_181
  [25:24] PI_RDLVL_GATE_EN_F1 — Enable the PI gate training module for frequency set 1.
  [17:16] PI_RDLVL_EN_F1 — Enable the PI data eye training module for frequency set 1.
  [9:8] PI_RDLVL_GATE_EN_F0 — Enable the PI gate training module for frequency set 0.
  [1:0] PI_RDLVL_EN_F0 — Enable the PI data eye training module for frequency set 0.
0x22D8 DDRSS_PI_182
  [25:24] PI_RDLVL_RXCAL_EN_F0 — Enable RX Offset calibration (PATTERN 14,15) for read training for frequency set 0.
  [17:16] PI_RDLVL_PAT0_EN_F0 — Enable PATTERN-0 for read training for frequency set 0.
  [9:8] PI_RDLVL_GATE_EN_F2 — Enable the PI gate training module for frequency set 2.
  [1:0] PI_RDLVL_EN_F2 — Enable the PI data eye training module for frequency set 2.
0x22DC DDRSS_PI_183
  [25:24] PI_RDLVL_RXCAL_EN_F1 — Enable RX Offset calibration (PATTERN 14,15) for read training for frequency set 1.
  [17:16] PI_RDLVL_PAT0_EN_F1 — Enable PATTERN-0 for read training for frequency set 1.
  [9:8] PI_RDLVL_MULTI_EN_F0 — Enable Multi-pattern (from PI_RDLVL_PATTERN_START, total PI_RDLVL_PATTERN_NUM) for read training for frequency set 0.
  [1:0] PI_RDLVL_DFE_EN_F0 — Enable DFE (PATTERN 8,9) for read training for frequency set 0.
0x22E0 DDRSS_PI_184
  [25:24] PI_RDLVL_RXCAL_EN_F2 — Enable RX Offset calibration (PATTERN 14,15) for read training for frequency set 2.
  [17:16] PI_RDLVL_PAT0_EN_F2 — Enable PATTERN-0 for read training for frequency set 2.
  [9:8] PI_RDLVL_MULTI_EN_F1 — Enable Multi-pattern (from PI_RDLVL_PATTERN_START, total PI_RDLVL_PATTERN_NUM) for read training for frequency set 1.
  [1:0] PI_RDLVL_DFE_EN_F1 — Enable DFE (PATTERN 8,9) for read training for frequency set 1.
